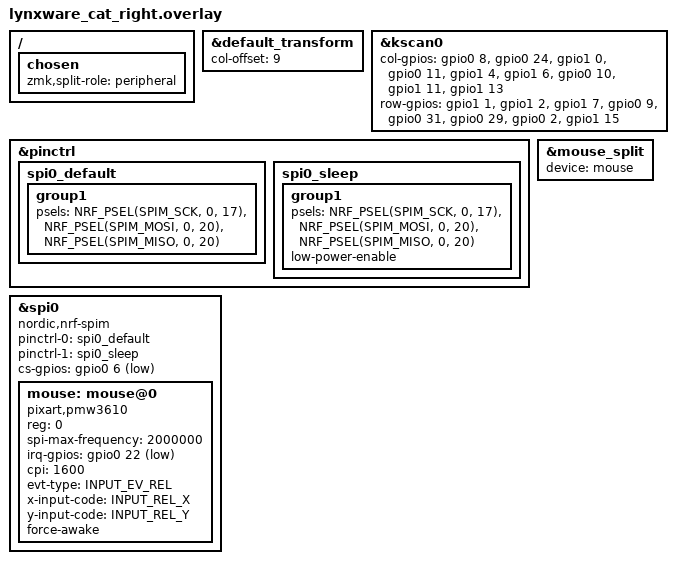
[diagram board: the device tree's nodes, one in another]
#include "lynxware_cat.dtsi"
#include <dt-bindings/zmk/input_transform.h>
#include <zephyr/dt-bindings/input/input-event-codes.h>

/ {
    chosen {
        zmk,split-role = "peripheral";
    };
};

&default_transform {
    col-offset = <9>;
};

&kscan0 {
    col-gpios
        = <&gpio0 8 (GPIO_ACTIVE_HIGH | GPIO_PULL_DOWN)>
        , <&gpio0 24 (GPIO_ACTIVE_HIGH | GPIO_PULL_DOWN)>
        , <&gpio1 0 (GPIO_ACTIVE_HIGH | GPIO_PULL_DOWN)>
        , <&gpio0 11 (GPIO_ACTIVE_HIGH | GPIO_PULL_DOWN)>
        , <&gpio1 4 (GPIO_ACTIVE_HIGH | GPIO_PULL_DOWN)>
        , <&gpio1 6 (GPIO_ACTIVE_HIGH | GPIO_PULL_DOWN)>
        , <&gpio0 10 (GPIO_ACTIVE_HIGH | GPIO_PULL_DOWN)>
        , <&gpio1 11 (GPIO_ACTIVE_HIGH | GPIO_PULL_DOWN)>
        , <&gpio1 13 (GPIO_ACTIVE_HIGH | GPIO_PULL_DOWN)>
        ;

    row-gpios
        = <&gpio1 1 GPIO_ACTIVE_HIGH>
        , <&gpio1 2 GPIO_ACTIVE_HIGH>
        , <&gpio1 7 GPIO_ACTIVE_HIGH>
        , <&gpio0 9 GPIO_ACTIVE_HIGH>
        , <&gpio0 31 GPIO_ACTIVE_HIGH>
        , <&gpio0 29 GPIO_ACTIVE_HIGH>
        , <&gpio0 2 GPIO_ACTIVE_HIGH>
        , <&gpio1 15 GPIO_ACTIVE_HIGH>
        ;
};

&pinctrl {
    spi0_default: spi0_default {
        group1 {
            psels = <NRF_PSEL(SPIM_SCK, 0, 17)>,
                    <NRF_PSEL(SPIM_MOSI, 0, 20)>,
                    <NRF_PSEL(SPIM_MISO, 0, 20)>;
        };
    };
    spi0_sleep: spi0_sleep {
        group1 {
            psels = <NRF_PSEL(SPIM_SCK, 0, 17)>,
                    <NRF_PSEL(SPIM_MOSI, 0, 20)>,
                    <NRF_PSEL(SPIM_MISO, 0, 20)>;
            low-power-enable;
        };
    };
};

&spi0 {
    status = "okay";
    compatible = "nordic,nrf-spim";
    pinctrl-0 = <&spi0_default>;
    pinctrl-1 = <&spi0_sleep>;
    pinctrl-names = "default", "sleep";
    cs-gpios = <&gpio0 6 GPIO_ACTIVE_LOW>;

    mouse: mouse@0 {
        status = "okay";
        compatible = "pixart,pmw3610";
        reg = <0>;
        spi-max-frequency = <2000000>;
        irq-gpios = <&gpio0 22 (GPIO_ACTIVE_LOW | GPIO_PULL_UP)>;
        cpi = <1600>;
        evt-type = <INPUT_EV_REL>;
        x-input-code = <INPUT_REL_X>;
        y-input-code = <INPUT_REL_Y>;
        force-awake;
    };
};

&mouse_split {
    status = "okay";
    device = <&mouse>;
};
